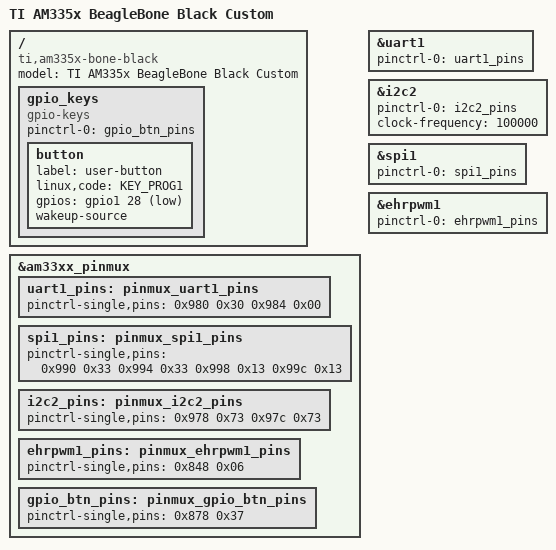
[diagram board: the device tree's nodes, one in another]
// SPDX-License-Identifier: GPL-2.0
/*
 * BeagleBone Black — custom device tree
 *
 * Based on am335x-boneblack.dts with custom peripherals:
 *   UART1, I2C2, SPI1, EHRPWM1A, GPIO button (P9.12)
 *
 * Pin allocation strategy:
 *   - I2C2 (not I2C1): frees SPI0 pins (P9.17/18)
 *   - SPI1 (not SPI0): no conflict with UART2/I2C
 *   - UART1 on dedicated pins: no conflict
 *   - SPI0 pins remain free for future expansion
 */
/dts-v1/;

#include "am33xx.dtsi"
#include "am335x-bone-common.dtsi"
#include "am335x-boneblack-common.dtsi"
#include <dt-bindings/input/input.h>

/ {
	model = "TI AM335x BeagleBone Black Custom";
	compatible = "ti,am335x-bone-black", "ti,am335x-bone", "ti,am33xx";
};

/*
 * Pinmux entries
 *
 * Pad register format (Control Module base 0x44E10000):
 *   bits[2:0] = MUXMODE
 *   bit[3]    = PULLUDDIS  (0 = pull enabled)
 *   bit[4]    = PULLUP_EN  (1 = pullup, 0 = pulldown)
 *   bit[5]    = RXACTIVE   (1 = input buffer enabled)
 *   bit[6]    = SLEWCTRL   (1 = slow slew)
 */
&am33xx_pinmux {
	uart1_pins: pinmux_uart1_pins {
		pinctrl-single,pins = <
			0x980 0x30	/* P9.26 uart1_rxd  — INPUT  + PULLUP, MUX_MODE0 */
			0x984 0x00	/* P9.24 uart1_txd  — OUTPUT, MUX_MODE0 */
		>;
	};

	spi1_pins: pinmux_spi1_pins {
		pinctrl-single,pins = <
			/* SPI1: MUX_MODE3 on mcasp0 pads */
			0x990 0x33	/* P9.31 mcasp0_aclkx  — SPI1_SCLK, INPUT + PULLUP, MUX_MODE3 */
			0x994 0x33	/* P9.29 mcasp0_fsx    — SPI1_D0 (MOSI), INPUT + PULLUP, MUX_MODE3 */
			0x998 0x13	/* P9.30 mcasp0_axr0   — SPI1_D1 (MISO), INPUT + PULLDOWN, MUX_MODE3 */
			0x99c 0x13	/* P9.28 mcasp0_ahclkr — SPI1_CS0, INPUT + PULLDOWN, MUX_MODE3 */
		>;
	};

	i2c2_pins: pinmux_i2c2_pins {
		pinctrl-single,pins = <
			/* SLEWCTRL(slow) + RXACTIVE + PULLUP_EN, MUX_MODE3 = i2c2 */
			0x978 0x73	/* P9.20 uart1_ctsn — I2C2_SDA, MUX_MODE3 */
			0x97c 0x73	/* P9.19 uart1_rtsn — I2C2_SCL, MUX_MODE3 */
		>;
	};

	ehrpwm1_pins: pinmux_ehrpwm1_pins {
		pinctrl-single,pins = <
			/* AM335x TRM: gpmc_a2 pad, MUX_MODE6 = ehrpwm1A */
			0x848 0x06	/* P9.14 gpmc_a2    — EHRPWM1A, MUX_MODE6 */
		>;
	};

	gpio_btn_pins: pinmux_gpio_btn_pins {
		pinctrl-single,pins = <
			/* INPUT + PULLUP + RXACTIVE, MUX_MODE7 = gpio mode */
			0x878 0x37	/* P9.12 gpmc_be1n  — GPIO1_28, MUX_MODE7 */
		>;
	};
};

/* ------------------------------------------------------------------ */
/* UART1 — P9.24 (TX) / P9.26 (RX)                                   */
/* ------------------------------------------------------------------ */
&uart1 {
	status = "okay";
	pinctrl-names = "default";
	pinctrl-0 = <&uart1_pins>;
};

/* ------------------------------------------------------------------ */
/* I2C2 — P9.19 (SCL) / P9.20 (SDA) — 100 kHz                       */
/* ------------------------------------------------------------------ */
&i2c2 {
	status = "okay";
	pinctrl-names = "default";
	pinctrl-0 = <&i2c2_pins>;
	clock-frequency = <100000>;
};

/* ------------------------------------------------------------------ */
/* SPI1 — P9.28/29/30/31                                             */
/* ------------------------------------------------------------------ */
&spi1 {
	status = "okay";
	pinctrl-names = "default";
	pinctrl-0 = <&spi1_pins>;
};

/* ------------------------------------------------------------------ */
/* EHRPWM1A — P9.14                                                  */
/* ------------------------------------------------------------------ */
&ehrpwm1 {
	status = "okay";
	pinctrl-names = "default";
	pinctrl-0 = <&ehrpwm1_pins>;
};

/* ------------------------------------------------------------------ */
/* GPIO button — P9.12 (GPIO1_28), active-low, falling-edge IRQ      */
/* ------------------------------------------------------------------ */
/ {
	gpio_keys: gpio_keys {
		compatible = "gpio-keys";
		pinctrl-names = "default";
		pinctrl-0 = <&gpio_btn_pins>;

		button {
			label = "user-button";
			linux,code = <KEY_PROG1>;
			gpios = <&gpio1 28 GPIO_ACTIVE_LOW>;
			wakeup-source;
		};
	};
};
